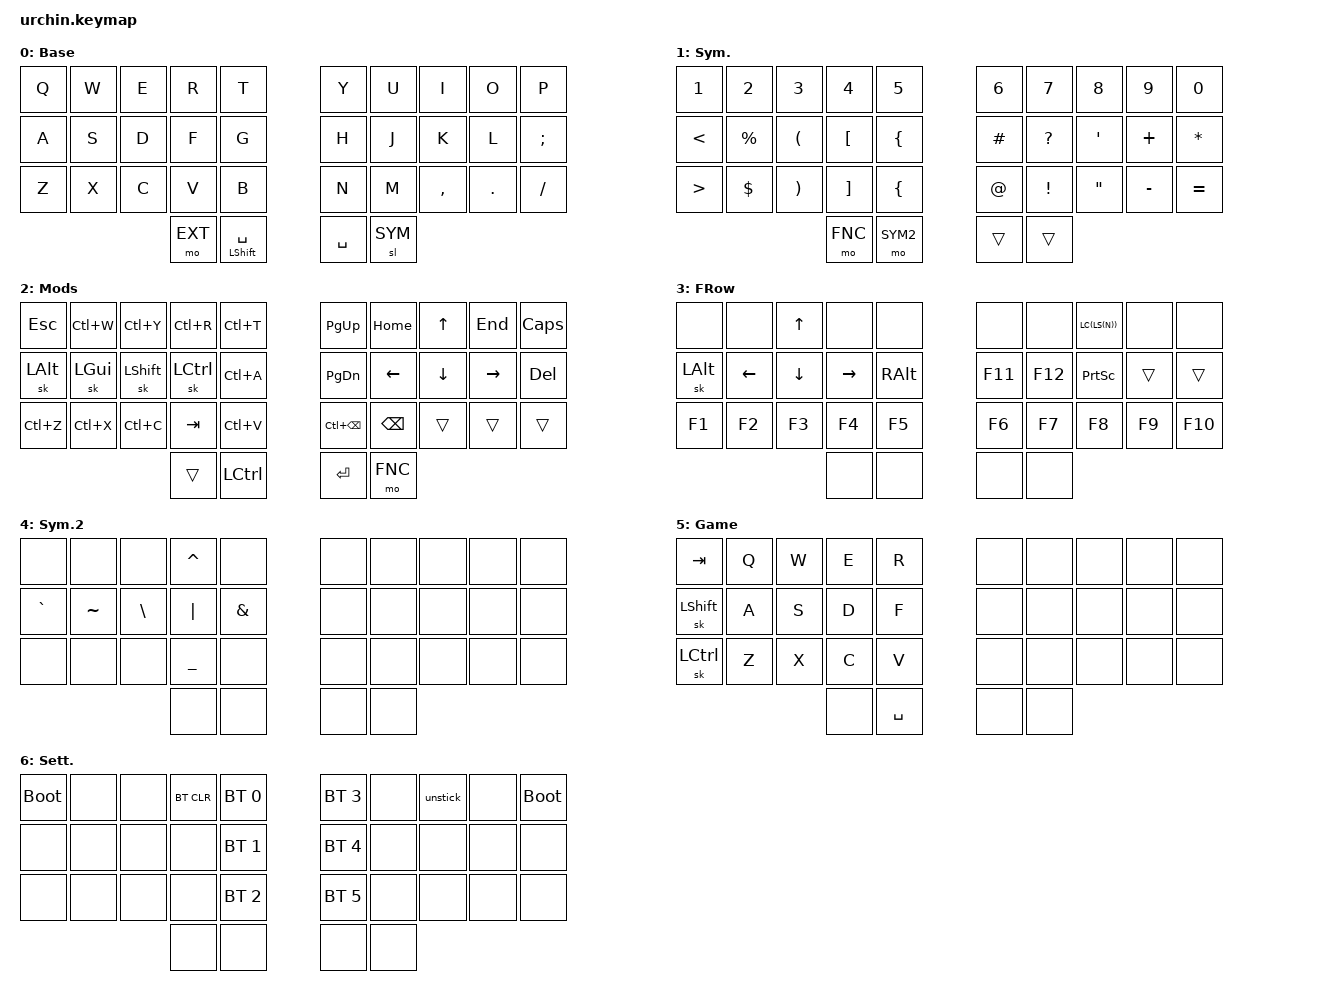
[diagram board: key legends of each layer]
/*
 * Copyright (c) 2020 duckyb
 *
 * SPDX-License-Identifier: MIT
 */

#include <behaviors.dtsi>
#include <dt-bindings/zmk/keys.h>
#include <dt-bindings/zmk/bt.h>
#include <dt-bindings/zmk/outputs.h>
// #include "keymap_italian.h"
// Layer definitions
#define BASE 0
#define SYM 1
#define EXT 2
#define FNC 3
#define SYM2 4
#define GAME 5
#define SETTINGS 6
// -----------------

&sk {
	// don't release mods on other mods presses
	ignore-modifiers;
};


/ {
	behaviors {
		// Enables holding the first mod-tap key
		// by performing a tap-release-hold sequence.
		// To use it: "&qt KEYCODE1 KEYCODE2"
		qt: quick_tap {
			compatible = "zmk,behavior-hold-tap";
			label = "QUICK_TAP";
			#binding-cells = <2>;
			flavor = "hold-preferred";
			tapping-term-ms = <200>;
			quick-tap-ms = <200>;
			bindings = <&kp>, <&kp>;
		};
	};

	macros {
		// sometimes my device thinks a modifier is being held down
		// pressing all modifiers fixes it.
		unstick: unstick {
			label = "ZM_unstick";
			compatible = "zmk,behavior-macro";
			#binding-cells = <0>;
			bindings = <&kp LSHIFT &kp RSHIFT &kp LCTRL &kp RCTRL &kp LALT &kp RALT &kp LGUI &kp RGUI>;
		};
	};

	combos {
		compatible = "zmk,combos";
		// both right thumb keys
		combo_game {
			timeout-ms = <200>;
			key-positions = <32 33>;
			bindings = <&tog GAME>;
		};
		// internal-left & external-right thumb keys
		combo_sym2 {
			timeout-ms = <200>;
			key-positions = <31 33>;
			bindings = <&mo SYM2>;
		};
		// both left thumb keys
		combo_settings {
			timeout-ms = <200>;
			key-positions = <30 31>;
			bindings = <&mo SETTINGS>;
		};
		// left index & middle fingers (home-row)
		// hold control & space for Adobe workflow
		combo_ctrl_space {
			timeout-ms = <200>;
			key-positions = <12 13>;
			bindings = <&kp LC(SPACE)>;
			layers = <BASE>;
		};
	};

	keymap {
		compatible = "zmk,keymap";
		// Base alpha layer
		default_layer {
			label = "Base";
			bindings = <
			&kp Q &kp W &kp E &kp R &kp T           &kp Y &kp U  &kp I     &kp O   &kp P 
			&kp A &kp S &kp D &kp F &kp G           &kp H &kp J  &kp K     &kp L &kp SEMI
			&kp Z &kp X &kp C &kp V &kp B           &kp N &kp M  &kp COMMA &kp DOT &kp FSLH
							&mo EXT &qt LSHIFT SPACE           &kp SPACE &sl SYM
			>;
		};

		// Numbers and high frequency symbols
		sym_layer {
			label = "Sym.";
			bindings = <
			&kp N1 &kp N2 &kp N3 &kp N4 &kp N5		                           &kp N6 &kp N7 &kp N8 &kp N9 &kp N0
			&kp LT &kp PRCNT &kp LPAR &kp LBKT &kp LBRC  			&kp HASH &kp QMARK &kp SQT &kp PLUS &kp STAR
			&kp GT &kp DLLR &kp RPAR &kp RBKT &kp LBRC  			&kp AT &kp EXCL &kp DQT &kp MINUS &kp EQUAL
							&mo FNC  &mo SYM2       &trans &trans
			>;
		};

		// Main modifiers and arrow keys
		ext_layer {
			label = "Mods";
			bindings = <
			&kp ESC  &kp LC(W) &kp LC(Y)  &kp LC(R)  &kp LC(T)   		&kp PG_UP  &kp HOME &kp UP &kp END &kp CAPS
			&sk LALT &sk LGUI  &sk LSHIFT  &sk LCTRL  &kp LC(A)			&kp PG_DN &kp LEFT  &kp DOWN  &kp RIGHT   &kp DEL
			&kp LC(Z)  &kp LC(X) &kp LC(C) &kp TAB   &kp LC(V)          		&kp LC(BSPC) &kp BSPC &trans &trans  &trans
								  &trans &kp LCTRL    &kp ENTER  &mo FNC 
			>;
		};

		// Function keys with modifiers
		fnc_layer {
			label = "FRow";
			bindings = <
			&none &none &kp UP &none &none				          &none &none LC(LS(N)) &none &none 
			&sk LALT &kp LEFT &kp DOWN &kp RIGHT &kp RALT     &kp F11 &kp F12  &kp PRINTSCREEN &trans &trans
			&kp F1 &kp F2 &kp F3 &kp F4 &kp F5                  &kp F6 &kp F7 &kp F8 &kp F9 &kp F10
							  &none &none              &none &none  
			>;
		};

		// Low frequency symbols.
		symbols_2_layer {
			label = "Sym.2";
			bindings = <
			&none &none &none &kp CARET &none         			&none &none &none &none &none 
			&kp GRAVE &kp TILDE &kp BSLH &kp PIPE &kp AMPS         	&none &none &none &none &none
			&none &none &none &kp UNDER &none			&none &none &none &none &none
								&none &none        	&none &none 
			>;
		};

		// Layer made to lock into traditional gaming mode.
		game_layer {
			label = "Game";
			bindings = <
			&kp TAB &kp Q &kp W &kp E &kp R                         &none &none &none &none &none 
			&sk LSHIFT &kp A &kp S &kp D &kp F 		        &none &none &none &none &none
			&sk LCTRL &kp Z &kp X &kp C &kp V				&none &none &none &none &none
						&none &kp SPACE                         &none &none 
			>;
		};

		// Used to change the keyboard's settings.
		settings_layer {
				label = "Sett.";
				bindings = <
				&bootloader &none &none &bt BT_CLR &bt BT_SEL 0               &bt BT_SEL 3 &none &unstick &none &bootloader 
				&none &none &none &none      &bt BT_SEL 1 						  &bt BT_SEL 4 &none &none &none &none
				&none &none &none &none      &bt BT_SEL 2               &bt BT_SEL 5 &none &none &none &none
										&none &none                         &none &none 
				>;
		};
	};
};
